# STM32WB55x register map
File version: 1.0
CPU: CM4 r0p1, little endian, 4 interrupt priority bits
Registers are 32-bit, read-write, reset 0x0 unless marked. A register's access mark holds for its fields unless they carry their own. Offsets are from the block's base; [hi:lo] are bit positions; {n}, {i} and the like mark numbered series; 'fields as' and 'values as' point back to an identical list.

## TSC
Base 0x40024000
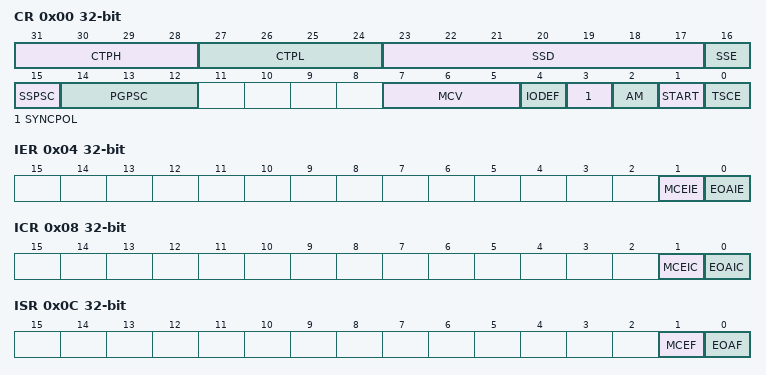
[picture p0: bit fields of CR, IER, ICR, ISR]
0x00 CR
  [31:28] CTPH, [27:24] CTPL, [23:17] SSD, [16] SSE, [15] SSPSC, [14:12] PGPSC, [7:5] MCV, [4] IODEF, [3] SYNCPOL, [2] AM, [1] START, [0] TSCE
0x04 IER
  [1] MCEIE, [0] EOAIE
0x08 ICR
  [1] MCEIC, [0] EOAIC
0x0C ISR
  [1] MCEF, [0] EOAF
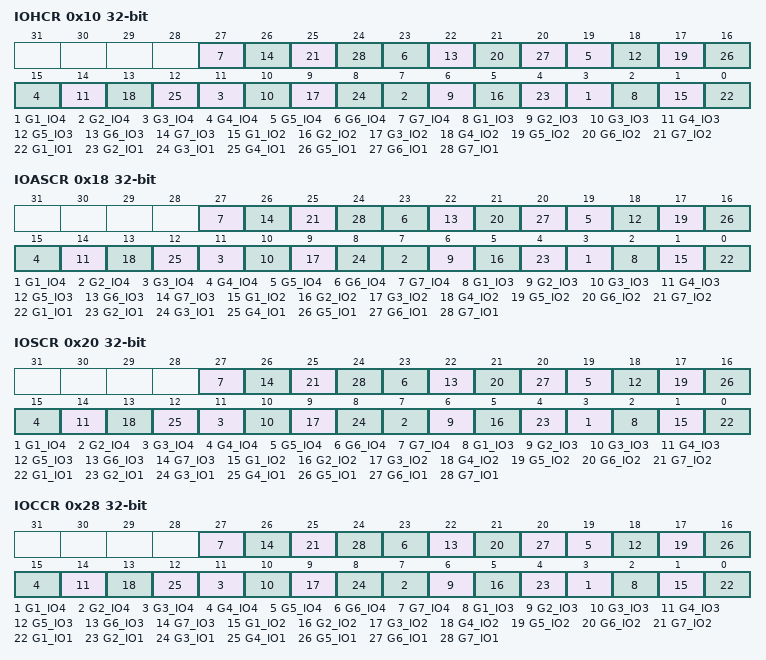
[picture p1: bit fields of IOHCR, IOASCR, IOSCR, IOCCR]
0x10 IOHCR
  [4n-1] G{n}_IO4 (n=1..7), [4n-2] G{n}_IO3 (n=1..7), [4n-3] G{n}_IO2 (n=1..7), [4n-4] G{n}_IO1 (n=1..7)
0x18 IOASCR
  fields as IOHCR
0x20 IOSCR
  fields as IOHCR
0x28 IOCCR
  fields as IOHCR
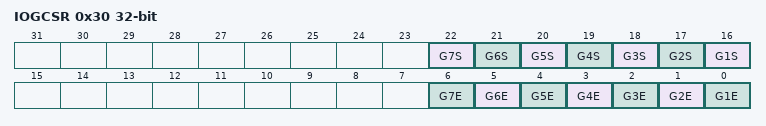
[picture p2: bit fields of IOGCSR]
0x30 IOGCSR
  [n+15] G{n}S (n=1..7), [n-1] G{n}E (n=1..7)
{0x30+4i} IOG{i}CR (i=1..7)
  [13:0] CNT

## RNG
Base 0x58001000
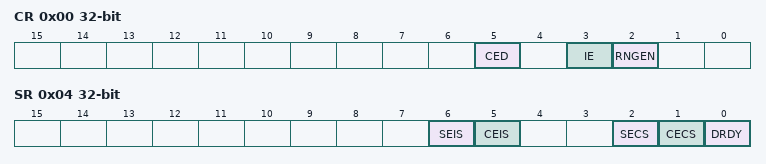
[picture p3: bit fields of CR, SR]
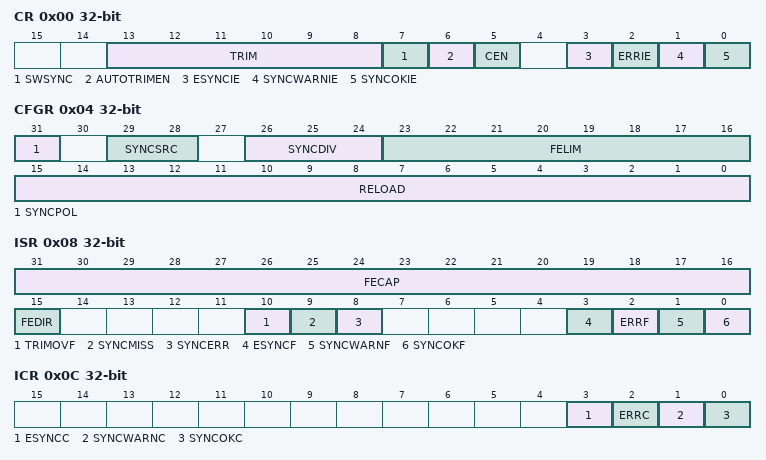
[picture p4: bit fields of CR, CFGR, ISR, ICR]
0x00 CR
  [5] CED, [3] IE, [2] RNGEN
0x04 SR
  [6] SEIS, [5] CEIS, [2] SECS, [1] CECS, [0] DRDY
0x08 DR
  [31:0] RNDATA

## CRS
Base 0x40006000
0x00 CR
  [13:8] TRIM, [7] SWSYNC, [6] AUTOTRIMEN, [5] CEN, [3] ESYNCIE, [2] ERRIE, [1] SYNCWARNIE, [0] SYNCOKIE
0x04 CFGR
  [31] SYNCPOL, [29:28] SYNCSRC, [26:24] SYNCDIV, [23:16] FELIM, [15:0] RELOAD
0x08 ISR
  [31:16] FECAP, [15] FEDIR, [10] TRIMOVF, [9] SYNCMISS, [8] SYNCERR, [3] ESYNCF, [2] ERRF, [1] SYNCWARNF, [0] SYNCOKF
0x0C ICR
  [3] ESYNCC, [2] ERRC, [1] SYNCWARNC, [0] SYNCOKC

## RTC
Base 0x40002800
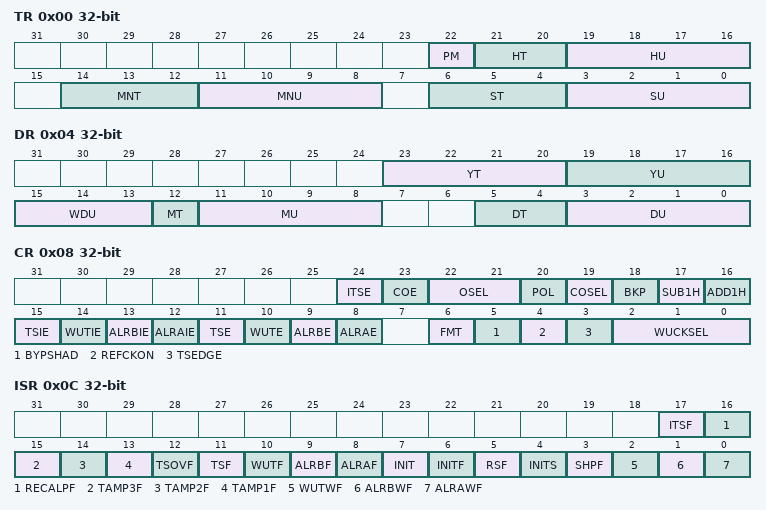
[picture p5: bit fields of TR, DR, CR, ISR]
0x00 TR
  [22] PM, [21:20] HT, [19:16] HU, [14:12] MNT, [11:8] MNU, [6:4] ST, [3:0] SU
0x04 DR
  [23:20] YT, [19:16] YU, [15:13] WDU, [12] MT, [11:8] MU, [5:4] DT, [3:0] DU
0x08 CR
  [24] ITSE, [23] COE, [22:21] OSEL, [20] POL, [19] COSEL, [18] BKP, [17] SUB1H, [16] ADD1H, [15] TSIE, [14] WUTIE, [13] ALRBIE, [12] ALRAIE, [11] TSE, [10] WUTE, [9] ALRBE, [8] ALRAE, [6] FMT, [5] BYPSHAD, [4] REFCKON, [3] TSEDGE, [2:0] WUCKSEL
0x0C ISR
  [17] ITSF, [16] RECALPF, [15] TAMP3F, [14] TAMP2F, [13] TAMP1F, [12] TSOVF, [11] TSF, [10] WUTF, [9] ALRBF, [8] ALRAF, [7] INIT, [6] INITF, [5] RSF, [4] INITS, [3] SHPF, [2] WUTWF, [1] ALRBWF, [0] ALRAWF
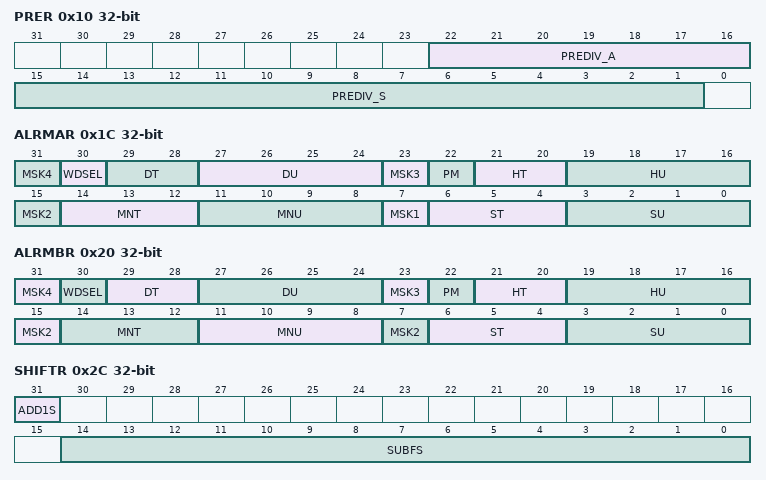
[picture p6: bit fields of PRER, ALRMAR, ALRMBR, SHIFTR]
0x10 PRER
  [22:16] PREDIV_A, [15:1] PREDIV_S
0x14 WUTR
  [15:0] WUT
0x1C ALRMAR
  [8n-1] MSK{n} (n=1..4), [30] WDSEL, [29:28] DT, [27:24] DU, [22] PM, [21:20] HT, [19:16] HU, [14:12] MNT, [11:8] MNU, [6:4] ST, [3:0] SU
0x20 ALRMBR
  [31] MSK4, [30] WDSEL, [29:28] DT, [27:24] DU, [23] MSK3, [22] PM, [21:20] HT, [19:16] HU, [15] MSK2, [14:12] MNT, [11:8] MNU, [7] MSK2, [6:4] ST, [3:0] SU
0x24 WPR
  [7:0] KEY
0x28 SSR
  [15:0] SS
0x2C SHIFTR
  [31] ADD1S, [14:0] SUBFS
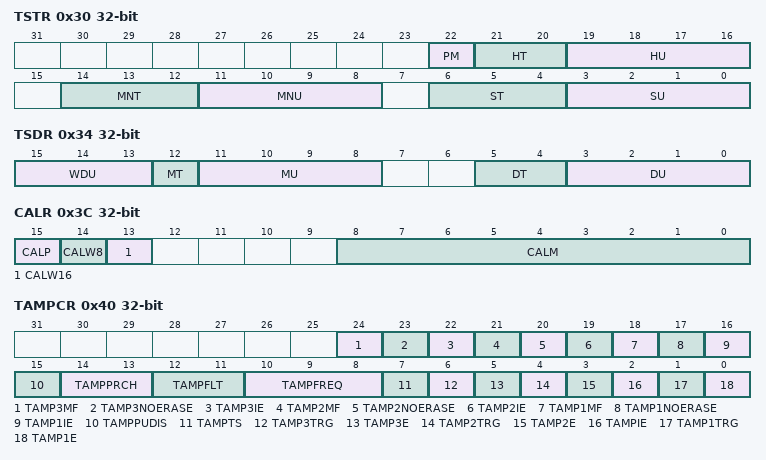
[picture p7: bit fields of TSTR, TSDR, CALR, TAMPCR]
0x30 TSTR
  fields as TR
0x34 TSDR
  [15:13] WDU, [12] MT, [11:8] MU, [5:4] DT, [3:0] DU
0x38 TSSSR
  [15:0] SS
0x3C CALR
  [15] CALP, [14] CALW8, [13] CALW16, [8:0] CALM
0x40 TAMPCR
  [24] TAMP3MF, [23] TAMP3NOERASE, [22] TAMP3IE, [21] TAMP2MF, [20] TAMP2NOERASE, [19] TAMP2IE, [18] TAMP1MF, [17] TAMP1NOERASE, [16] TAMP1IE, [15] TAMPPUDIS, [14:13] TAMPPRCH, [12:11] TAMPFLT, [10:8] TAMPFREQ, [7] TAMPTS, [6] TAMP3TRG, [5] TAMP3E, [4] TAMP2TRG, [3] TAMP2E, [2] TAMPIE, [1] TAMP1TRG, [0] TAMP1E
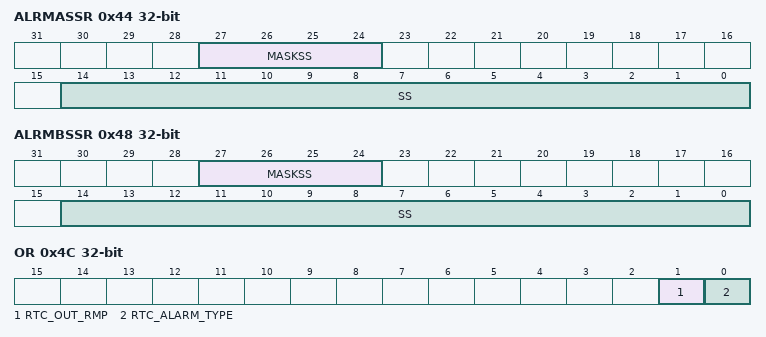
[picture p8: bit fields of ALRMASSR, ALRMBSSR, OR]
0x44 ALRMASSR
  [27:24] MASKSS, [14:0] SS
0x48 ALRMBSSR
  [27:24] MASKSS, [14:0] SS
0x4C OR
  [1] RTC_OUT_RMP, [0] RTC_ALARM_TYPE
0x50 BKP0R
  [31:0] BKP
{0x50+4i} RKP{i}R (i=1..18)
  [31:0] BKP
0x9C BKP19R
  [31:0] BKP

## GPIOA
Base 0x48000000
Same registers: GPIOB 0x48000400, GPIOC 0x48000800, GPIOD 0x48000C00
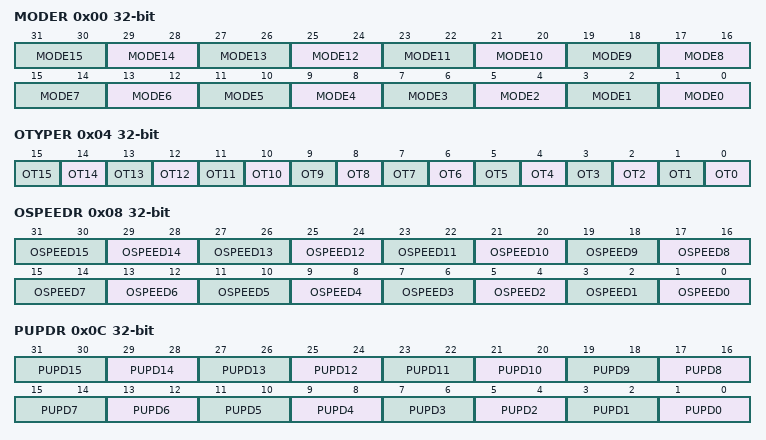
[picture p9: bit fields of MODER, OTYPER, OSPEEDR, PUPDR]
0x00 MODER
  [2n+1:2n] MODE{n} (n=0..15)
0x04 OTYPER
  [n] OT{n} (n=0..15)
0x08 OSPEEDR
  [2n+1:2n] OSPEED{n} (n=0..15)
0x0C PUPDR
  [2n+1:2n] PUPD{n} (n=0..15)
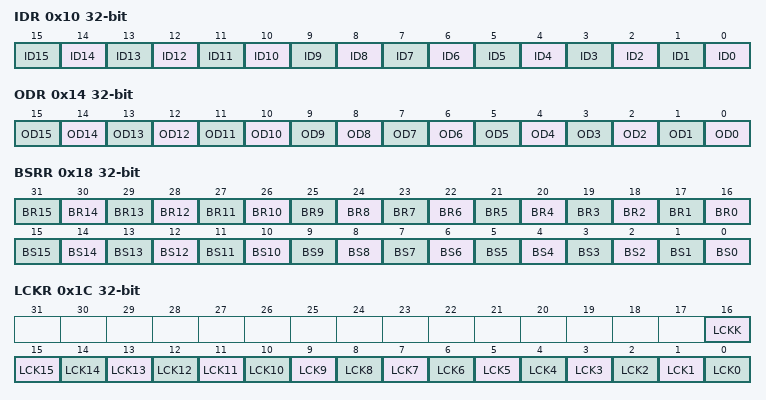
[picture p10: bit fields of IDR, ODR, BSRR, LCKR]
0x10 IDR
  [n] ID{n} (n=0..15)
0x14 ODR
  [n] OD{n} (n=0..15)
0x18 BSRR
  [n+16] BR{n} (n=0..15), [n] BS{n} (n=0..15)
0x1C LCKR
  [16] LCKK, [n] LCK{n} (n=0..15)
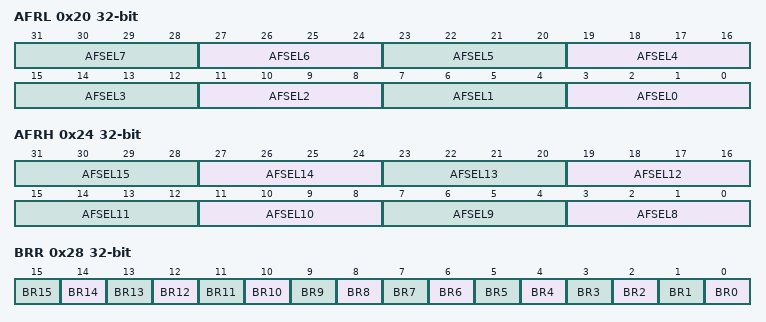
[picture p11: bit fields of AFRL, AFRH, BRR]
0x20 AFRL
  [4n+3:4n] AFSEL{n} (n=0..7)
0x24 AFRH
  [4n-29:4n-32] AFSEL{n} (n=8..15)
0x28 BRR
  [n] BR{n} (n=0..15)

## GPIOE
Base 0x48001000
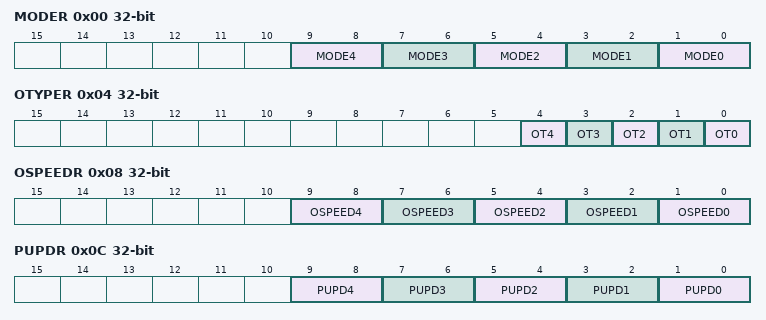
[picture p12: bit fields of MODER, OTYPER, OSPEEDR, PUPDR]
0x00 MODER
  [2n+1:2n] MODE{n} (n=0..4)
0x04 OTYPER
  [n] OT{n} (n=0..4)
0x08 OSPEEDR
  [2n+1:2n] OSPEED{n} (n=0..4)
0x0C PUPDR
  [2n+1:2n] PUPD{n} (n=0..4)
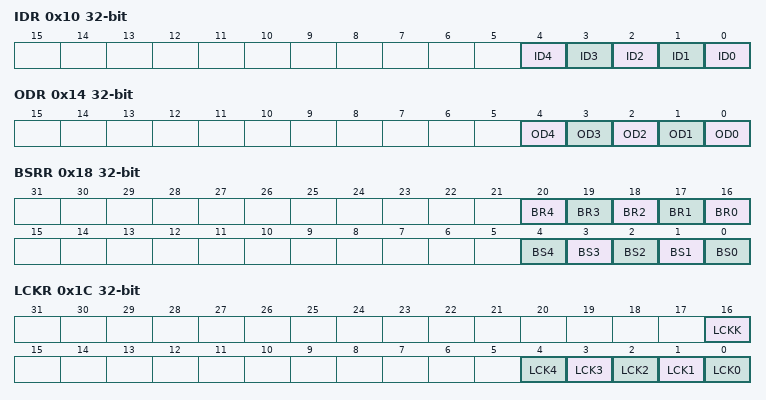
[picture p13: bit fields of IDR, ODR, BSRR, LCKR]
0x10 IDR
  [n] ID{n} (n=0..4)
0x14 ODR
  [n] OD{n} (n=0..4)
0x18 BSRR
  [n+16] BR{n} (n=0..4), [n] BS{n} (n=0..4)
0x1C LCKR
  [16] LCKK, [n] LCK{n} (n=0..4)
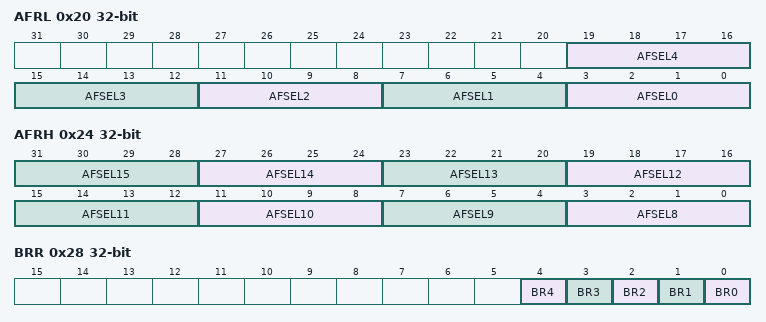
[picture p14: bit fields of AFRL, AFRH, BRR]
0x20 AFRL
  [4n+3:4n] AFSEL{n} (n=0..4)
0x24 AFRH
  [4n-29:4n-32] AFSEL{n} (n=8..15)
0x28 BRR
  [n] BR{n} (n=0..4)
